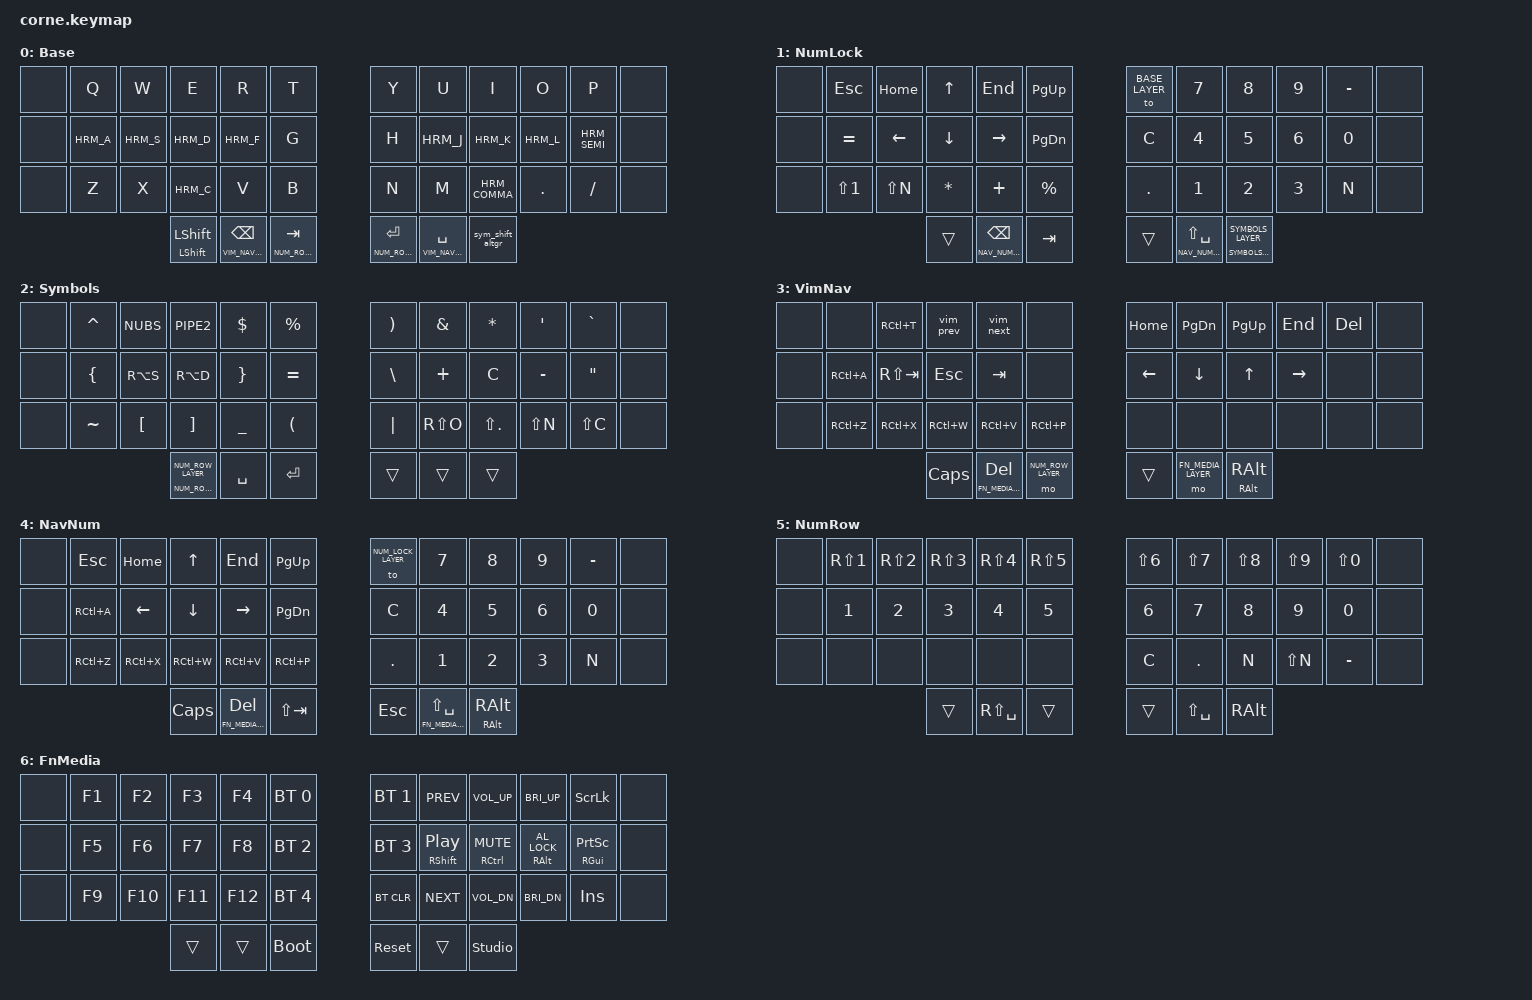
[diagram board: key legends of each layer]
/*
 * Chocofi keymap — adapted from Selenium/Quacken
 * Active options: KB_LAYOUT_ERGOL | LINUX | HT_HOME_ROW_MODS | VIM_NAVIGATION | HRM_SHIFT
 */

#include <behaviors.dtsi>
#include <dt-bindings/zmk/keys.h>
#include <dt-bindings/zmk/bt.h>

// ── Ergo-L shortcuts (Linux: CMD = RC) ────────────────────────────────────

#define X_UNDO  &kp RC(Z)
#define X_CUT   &kp RC(X)
#define X_COPY  &kp RC(W)
#define X_PASTE &kp RC(V)
#define X_REDO  &kp RC(P)
#define X_CTL_W &kp RC(T)
#define X_SAVE  &kp RC(S)
#define X_ALL   &kp RC(A)
#define X_SHTAB &kp RS(TAB)

// ── Arsenik symbol layer — keycodes as seen by an Ergo-L host ─────────────

#define S_CARET &kp CARET
#define S_LT    &kp NUBS
#define S_GT    &kp PIPE2
#define S_DLLR  &kp DLLR
#define S_PRCNT &kp PRCNT
#define S_AT    &kp RPAR
#define S_AMPS  &kp AMPS
#define S_STAR  &kp STAR
#define S_SQT   &kp SQT
#define S_GRAVE &kp GRAVE

#define S_LBRC  &kp LBRC
#define S_LPAR  &kp RA(S)
#define S_RPAR  &kp RA(D)
#define S_RBRC  &kp RBRC
#define S_EQUAL &kp EQUAL
#define S_BSLH  &kp BSLH
#define S_PLUS  &kp PLUS
#define S_MINUS &kp C
#define S_FSLH  &kp MINUS
#define S_DQT   &kp DQT

#define S_TILDE &kp TILDE
#define S_LBKT  &kp LBKT
#define S_RBKT  &kp RBKT
#define S_UNDER &kp UNDER
#define S_HASH  &kp LPAR
#define S_PIPE  &kp PIPE
#define S_EXCL  &kp RS(O)
#define S_SEMI  &kp LS(DOT)
#define S_COLON &kp LS(N)
#define S_QMARK &kp LS(C)

#define S_COMMA &kp DOT
#define S_DOT   &kp N
#define S_MONEY &kp LS(N1)

#define S_N0  &kp N0
#define S_N1  &kp N1
#define S_N2  &kp N2
#define S_N3  &kp N3
#define S_N4  &kp N4
#define S_N5  &kp N5
#define S_N6  &kp N6
#define S_N7  &kp N7
#define S_N8  &kp N8
#define S_N9  &kp N9

// ── Layer indices ──────────────────────────────────────────────────────────

#define BASE_LAYER     0
#define NUM_LOCK_LAYER 1
#define SYMBOLS_LAYER  2
#define VIM_NAV_LAYER  3
#define NAV_NUM_LAYER  4
#define NUM_ROW_LAYER  5
#define FN_MEDIA_LAYER 6

// ── Timing ─────────────────────────────────────────────────────────────────

#define TAPPING_TERM       300
#define SHORT_TAPPING_TERM 150
#define QUICK_TAP          200

// ── HRM (Linux + HRM_SHIFT) ────────────────────────────────────────────────

#define H_A     &hrm LGUI
#define H_S     &hrm RALT
#define H_D     &hrm LCTL
#define H_F     &hrm LSHIFT
#define H_J     &hrm RSHIFT
#define H_K     &hrm RCTL
#define H_L     &hrm RALT
#define H_SEMI  &hrm RGUI
#define H_C     &hrm LALT
#define H_COMMA &hrm LALT

#define HRM_A     H_A A
#define HRM_S     H_S S
#define HRM_D     H_D D
#define HRM_F     H_F F
#define HRM_J     H_J J
#define HRM_K     H_K K
#define HRM_L     H_L L
#define HRM_SEMI  H_SEMI SEMI
#define HRM_C     H_C C
#define HRM_COMMA H_COMMA COMMA

// ── Thumb keys (VIM_NAVIGATION + HT_HOME_ROW_MODS) ────────────────────────

#define LTHUMB_TUCK  &bsk LSHIFT LSHIFT
#define LTHUMB_HOME  &sc VIM_NAV_LAYER BACKSPACE
#define LTHUMB_REACH &sc NUM_ROW_LAYER TAB
#define RTHUMB_REACH &sc NUM_ROW_LAYER ENTER
#define RTHUMB_HOME  &lt VIM_NAV_LAYER SPACE
#define RTHUMB_TUCK  &sym_shift_altgr

// ── Global behavior overrides ──────────────────────────────────────────────

&sl { ignore-modifiers; };
&sk { quick-release; };
&mt {
    tapping-term-ms = <SHORT_TAPPING_TERM>;
    quick-tap-ms    = <QUICK_TAP>;
};
&lt {
    tapping-term-ms = <TAPPING_TERM>;
    quick-tap-ms    = <QUICK_TAP>;
};

/ {
    behaviors {
        hrm: homerow_mods {
            compatible = "zmk,behavior-hold-tap";
            #binding-cells = <2>;
            tapping-term-ms = <TAPPING_TERM>;
            quick-tap-ms    = <QUICK_TAP>;
            flavor          = "tap-preferred";
            bindings        = <&kp>, <&kp>;
        };

        // hold-preferred layer-tap for thumb keys that produce text when tapped
        sc: space_cadet {
            compatible = "zmk,behavior-hold-tap";
            #binding-cells = <2>;
            tapping-term-ms = <SHORT_TAPPING_TERM>;
            quick-tap-ms    = <QUICK_TAP>;
            flavor          = "hold-preferred";
            bindings        = <&mo>, <&kp>;
        };

        // one-shot layer via macro for robust timing
        osl: one_shot_layer {
            compatible = "zmk,behavior-macro-one-param";
            #binding-cells = <1>;
            tap-ms  = <0>;
            wait-ms = <0>;
            bindings = <&macro_param_1to1>, <&macro_tap &sl MACRO_PLACEHOLDER>;
        };

        // hold = momentary layer, tap = one-shot layer
        bsl: better_sticky_layer {
            compatible = "zmk,behavior-hold-tap";
            #binding-cells = <2>;
            tapping-term-ms = <TAPPING_TERM>;
            flavor          = "tap-preferred";
            bindings        = <&mo>, <&osl>;
        };

        // one-shot modifier via macro for robust timing
        osm: one_shot_modifier {
            compatible = "zmk,behavior-macro-one-param";
            #binding-cells = <1>;
            tap-ms  = <0>;
            wait-ms = <0>;
            bindings = <&macro_param_1to1>, <&macro_tap &sk MACRO_PLACEHOLDER>;
        };

        // hold = kp (held), tap = one-shot modifier
        bsk: better_sticky_key {
            compatible = "zmk,behavior-hold-tap";
            #binding-cells = <2>;
            tapping-term-ms = <TAPPING_TERM>;
            flavor          = "tap-preferred";
            bindings        = <&kp>, <&osm>;
        };

        // go to base layer then hold a key
        lkp: goto_base_keypress {
            compatible = "zmk,behavior-macro-one-param";
            #binding-cells = <1>;
            wait-ms = <0>;
            tap-ms  = <0>;
            bindings =
                <&macro_tap &to BASE_LAYER>,
                <&macro_param_1to1>,
                <&macro_press &kp MACRO_PLACEHOLDER>,
                <&macro_pause_for_release>,
                <&macro_param_1to1>,
                <&macro_release &kp MACRO_PLACEHOLDER>;
        };

        // go to base layer then one-shot modifier
        losm: goto_base_osm {
            compatible = "zmk,behavior-macro-one-param";
            #binding-cells = <1>;
            wait-ms = <0>;
            tap-ms  = <0>;
            bindings =
                <&macro_tap &to BASE_LAYER>,
                <&macro_param_1to1>,
                <&macro_tap &sk MACRO_PLACEHOLDER>;
        };

        // bsk that returns to base layer first (used for AltGr on nav layers)
        lbsk: bsk_on_base {
            compatible = "zmk,behavior-hold-tap";
            #binding-cells = <2>;
            tapping-term-ms = <TAPPING_TERM>;
            flavor          = "tap-preferred";
            bindings        = <&lkp>, <&losm>;
        };

        // right tuck: sticky Symbols; Shift+tuck: sticky AltGr
        sym_shift_altgr_inner: sym_shift_altgr_inner {
            compatible = "zmk,behavior-mod-morph";
            #binding-cells = <0>;
            bindings  = <&bsl SYMBOLS_LAYER SYMBOLS_LAYER>, <&bsk RALT RALT>;
            mods      = <(MOD_LSFT|MOD_RSFT)>;
            keep-mods = <(MOD_LSFT|MOD_RSFT)>;
        };

        sym_shift_altgr: sym_shift_altgr {
            compatible = "zmk,behavior-mod-morph";
            #binding-cells = <0>;
            bindings  = <&sym_shift_altgr_inner>, <&bsl SYMBOLS_LAYER SYMBOLS_LAYER>;
            mods      = <(MOD_LCTL|MOD_RCTL|MOD_LGUI|MOD_RGUI|MOD_LALT)>;
            keep-mods = <(MOD_LCTL|MOD_RCTL|MOD_LGUI|MOD_RGUI|MOD_LALT)>;
        };

        // Alt+prev/next tab; without Alt: browser back/forward (backtick/Shift+backtick)
        vim_prev: vim_prev {
            compatible = "zmk,behavior-mod-morph";
            #binding-cells = <0>;
            bindings  = <&kp LA(LEFT)>, <&kp LS(GRAVE)>;
            mods      = <(MOD_LALT|MOD_LGUI)>;
            keep-mods = <(MOD_LALT|MOD_LGUI)>;
        };

        vim_next: vim_next {
            compatible = "zmk,behavior-mod-morph";
            #binding-cells = <0>;
            bindings  = <&kp LA(RIGHT)>, <&kp GRAVE>;
            mods      = <(MOD_LALT|MOD_LGUI)>;
            keep-mods = <(MOD_LALT|MOD_LGUI)>;
        };
    };

    keymap {
        compatible = "zmk,keymap";

        // 0. Base layer
        base_layer: base_layer {
            display-name = "Base";
            bindings = <
                &none  &kp Q   &kp W   &kp E      &kp R  &kp T      &kp Y  &kp U   &kp I       &kp O    &kp P     &none
                &none  HRM_A   HRM_S   HRM_D      HRM_F  &kp G      &kp H  HRM_J   HRM_K       HRM_L    HRM_SEMI  &none
                &none  &kp Z   &kp X   HRM_C      &kp V  &kp B      &kp N  &kp M   HRM_COMMA   &kp DOT  &kp FSLH  &none
                       LTHUMB_TUCK  LTHUMB_HOME  LTHUMB_REACH    RTHUMB_REACH  RTHUMB_HOME  RTHUMB_TUCK
            >;
        };

        // 1. NumLock layer — stays on until deactivated
        num_lock_layer: num_lock_layer {
            display-name = "NumLock";
            bindings = <
                &none  &kp ESC  &kp HOME  &kp UP    &kp END    &kp PG_UP    &to BASE_LAYER  S_N7  S_N8  S_N9  S_FSLH  &none
                &none  S_EQUAL  &kp LEFT  &kp DOWN  &kp RIGHT  &kp PG_DN    S_MINUS         S_N4  S_N5  S_N6  S_N0    &none
                &none  S_MONEY  S_COLON   S_STAR    S_PLUS     S_PRCNT      S_COMMA         S_N1  S_N2  S_N3  S_DOT   &none
                       &trans   &sc NAV_NUM_LAYER BACKSPACE   &kp TAB    &trans  &lt NAV_NUM_LAYER LS(SPACE)  &bsl SYMBOLS_LAYER SYMBOLS_LAYER
            >;
        };

        // 2. Symbols layer — Arsenik layout
        symbols_layer: symbols_layer {
            display-name = "Symbols";
            bindings = <
                &none  S_CARET  S_LT    S_GT    S_DLLR   S_PRCNT    S_AT    S_AMPS  S_STAR   S_SQT    S_GRAVE  &none
                &none  S_LBRC   S_LPAR  S_RPAR  S_RBRC   S_EQUAL    S_BSLH  S_PLUS  S_MINUS  S_FSLH   S_DQT    &none
                &none  S_TILDE  S_LBKT  S_RBKT  S_UNDER  S_HASH     S_PIPE  S_EXCL  S_SEMI   S_COLON  S_QMARK  &none
                       &bsl NUM_ROW_LAYER NUM_ROW_LAYER   &kp SPACE  &kp ENTER    &trans  &trans  &trans
            >;
        };

        // 3. VimNav layer — HJKL + GUI shortcuts (left) / navigation (right)
        vim_nav_layer: vim_nav_layer {
            display-name = "VimNav";
            bindings = <
                &none  &none    X_CTL_W  &vim_prev  &vim_next  &none        &kp HOME  &kp PG_DN  &kp PG_UP  &kp END    &kp DEL  &none
                &none  X_ALL    X_SHTAB   &kp ESC   &kp TAB    &none        &kp LEFT  &kp DOWN   &kp UP     &kp RIGHT  &none    &none
                &none  X_UNDO   X_CUT    X_COPY     X_PASTE    X_REDO       &none     &none      &none      &none      &none    &none
                       &kp CAPS  &lt FN_MEDIA_LAYER DEL  &mo NUM_ROW_LAYER    &trans  &mo FN_MEDIA_LAYER  &lbsk RALT RALT
            >;
        };

        // 4. NavNum layer — inverted-T arrows (left) + numpad (right)
        nav_num_layer: nav_num_layer {
            display-name = "NavNum";
            bindings = <
                &none  &kp ESC  &kp HOME  &kp UP    &kp END    &kp PG_UP    &to NUM_LOCK_LAYER  S_N7  S_N8  S_N9  S_FSLH  &none
                &none  X_ALL    &kp LEFT  &kp DOWN  &kp RIGHT  &kp PG_DN    S_MINUS             S_N4  S_N5  S_N6  S_N0    &none
                &none  X_UNDO   X_CUT     X_COPY    X_PASTE    X_REDO       S_COMMA             S_N1  S_N2  S_N3  S_DOT   &none
                       &kp CAPS  &sc FN_MEDIA_LAYER DEL  &kp LS(TAB)    &kp ESCAPE  &lt FN_MEDIA_LAYER LS(SPACE)  &lbsk RALT RALT
            >;
        };

        // 5. NumRow layer — numbers on homerow, Shift+numbers accessible
        num_row_layer: num_row_layer {
            display-name = "NumRow";
            bindings = <
                &none  &kp RS(N1)  &kp RS(N2)  &kp RS(N3)  &kp RS(N4)  &kp RS(N5)    &kp LS(N6)  &kp LS(N7)  &kp LS(N8)  &kp LS(N9)  &kp LS(N0)  &none
                &none  &kp N1      &kp N2      &kp N3      &kp N4      &kp N5        &kp N6      &kp N7      &kp N8      &kp N9      &kp N0      &none
                &none  &none       &none       &none       &none       &none         S_MINUS     S_COMMA     S_DOT       S_COLON     S_FSLH      &none
                                   &trans      &kp RS(SPACE)  &trans      &trans  &kp LS(SPACE)  &kp RALT
            >;
        };

        // 6. FnMedia layer — F1-12 (left) + media / reset (right)
        fn_media_layer: fn_media_layer {
            display-name = "FnMedia";
            bindings = <
                &none  &kp F1  &kp F2   &kp F3   &kp F4   &bt BT_SEL 0    &bt BT_SEL 1  &kp C_PREV           &kp C_VOL_UP        &kp C_BRI_UP           &kp SLCK            &none
                &none  &kp F5  &kp F6   &kp F7   &kp F8   &bt BT_SEL 2    &bt BT_SEL 3  &hrm RSHIFT C_PP     &hrm RCTL C_MUTE    &hrm RALT C_AL_LOCK    &hrm RGUI PSCRN     &none
                &none  &kp F9  &kp F10  &kp F11  &kp F12  &bt BT_SEL 4    &bt BT_CLR    &kp C_NEXT           &kp C_VOL_DN        &kp C_BRI_DN           &kp INS             &none
                               &trans   &trans   &bootloader    &sys_reset  &trans  &studio_unlock
            >;
        };
    };
};
